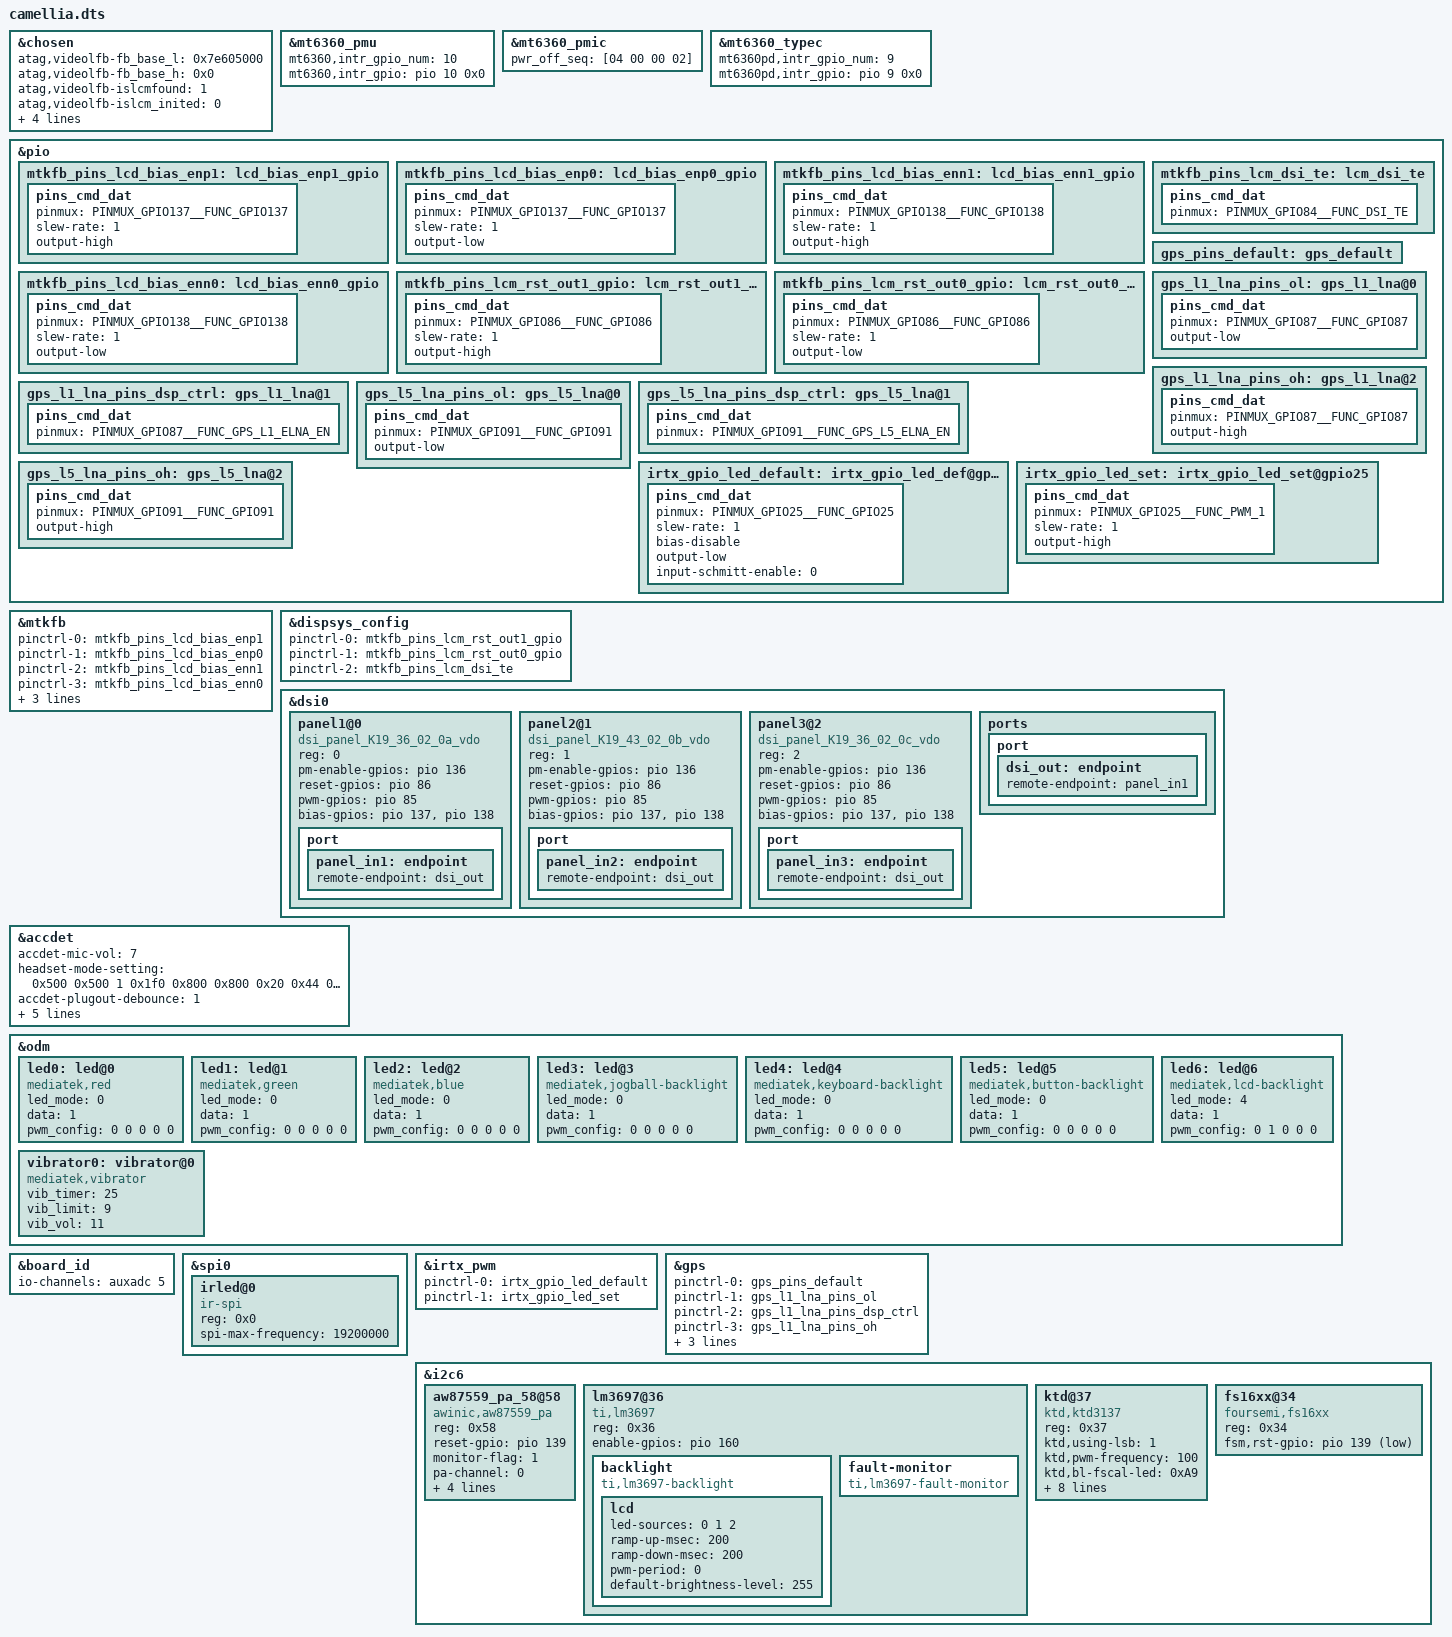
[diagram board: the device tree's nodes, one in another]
/*
 * Mediatek's mt6833 SoC device tree source
 *
 * Copyright (C) 2016 MediaTek Inc.
 * Copyright (C) 2021 XiaoMi, Inc.
 *
 * This program is free software; you can redistribute it and/or modify
 * it under the terms of the GNU General Public License version 2 as
 * published by the Free Software Foundation.
 *
 * This program is distributed in the hope that it will be useful,
 * but WITHOUT ANY WARRANTY; without even the implied warranty of
 * MERCHANTABILITY or FITNESS FOR A PARTICULAR PURPOSE.
 * See http://www.gnu.org/licenses/gpl-2.0.html for more details.
 */
/dts-v1/;
/plugin/;
#include <dt-bindings/interrupt-controller/irq.h>
#include <dt-bindings/interrupt-controller/arm-gic.h>
#ifndef CONFIG_FPGA_EARLY_PORTING
#include <dt-bindings/pinctrl/mt6833-pinfunc.h>
#endif

/* chosen */
&chosen {
	atag,videolfb-fb_base_l = <0x7e605000>;
	atag,videolfb-fb_base_h = <0x0>;
	atag,videolfb-islcmfound = <1>;
	atag,videolfb-islcm_inited = <0>;
	atag,videolfb-fps= <6000>;
	atag,videolfb-vramSize= <0x1be0000>;
	atag,videolfb-lcmname=
		"nt36672c_fhdp_dsi_vdo_90hz_tianma_lcm_drv";
};

&mt6360_pmu {
	mt6360,intr_gpio_num = <10>; /* direct defined GPIO num */
	mt6360,intr_gpio = <&pio 10 0x0>;
};

&mt6360_pmic {
	pwr_off_seq = [04 00 00 02];
};

/* BSP.Charge - 2020.11.02 - modify typec interrupt */
&mt6360_typec {
	mt6360pd,intr_gpio_num = <9>; /* direct defined GPIO num */
	mt6360pd,intr_gpio = <&pio 9 0x0>;
};

#ifndef CONFIG_FPGA_EARLY_PORTING
&pio {
	mtkfb_pins_lcd_bias_enp1: lcd_bias_enp1_gpio {
		pins_cmd_dat {
			pinmux = <PINMUX_GPIO137__FUNC_GPIO137>;
			slew-rate = <1>;
			output-high;
		};
	};

	mtkfb_pins_lcd_bias_enp0: lcd_bias_enp0_gpio {
		pins_cmd_dat {
			pinmux = <PINMUX_GPIO137__FUNC_GPIO137>;
			slew-rate = <1>;
			output-low;
		};
	};

	mtkfb_pins_lcd_bias_enn1: lcd_bias_enn1_gpio {
		pins_cmd_dat {
			pinmux = <PINMUX_GPIO138__FUNC_GPIO138>;
			slew-rate = <1>;
			output-high;
		};
	};

	mtkfb_pins_lcd_bias_enn0: lcd_bias_enn0_gpio {
		pins_cmd_dat {
			pinmux = <PINMUX_GPIO138__FUNC_GPIO138>;
			slew-rate = <1>;
			output-low;
		};
	};

	mtkfb_pins_lcm_rst_out1_gpio: lcm_rst_out1_gpio {
		pins_cmd_dat {
			pinmux = <PINMUX_GPIO86__FUNC_GPIO86>;
			slew-rate = <1>;
			output-high;
		};
	};

	mtkfb_pins_lcm_rst_out0_gpio: lcm_rst_out0_gpio {
		pins_cmd_dat {
			pinmux = <PINMUX_GPIO86__FUNC_GPIO86>;
			slew-rate = <1>;
			output-low;
		};
	};
	mtkfb_pins_lcm_dsi_te: lcm_dsi_te {
		pins_cmd_dat {
			pinmux = <PINMUX_GPIO84__FUNC_DSI_TE>;
		};
	};
};

&mtkfb {
	pinctrl-names = "lcd_bias_enp1_gpio", "lcd_bias_enp0_gpio",
		"lcd_bias_enn1_gpio", "lcd_bias_enn0_gpio",
		"lcm_rst_out1_gpio", "lcm_rst_out0_gpio",
		"mode_te_te";
	pinctrl-0 = <&mtkfb_pins_lcd_bias_enp1>;
	pinctrl-1 = <&mtkfb_pins_lcd_bias_enp0>;
	pinctrl-2 = <&mtkfb_pins_lcd_bias_enn1>;
	pinctrl-3 = <&mtkfb_pins_lcd_bias_enn0>;
	pinctrl-4 = <&mtkfb_pins_lcm_rst_out1_gpio>;
	pinctrl-5 = <&mtkfb_pins_lcm_rst_out0_gpio>;
	pinctrl-6 = <&mtkfb_pins_lcm_dsi_te>;
	status = "okay";
};
&dispsys_config {
	pinctrl-names =
		"lcm_rst_out1_gpio", "lcm_rst_out0_gpio",
		"mode_te_te";
	pinctrl-0 = <&mtkfb_pins_lcm_rst_out1_gpio>;
	pinctrl-1 = <&mtkfb_pins_lcm_rst_out0_gpio>;
	pinctrl-2 = <&mtkfb_pins_lcm_dsi_te>;
	status = "okay";
};

&dsi0 {
	status = "okay";
	#address-cells = <1>;
	#size-cells = <0>;
	/* BSP.lcm - 2020.11.19 - start */
	panel1@0 {
		compatible = "dsi_panel_K19_36_02_0a_vdo";
		reg = <0>;
		pm-enable-gpios = <&pio 136 0>;
		reset-gpios = <&pio 86 0>;
		pwm-gpios = <&pio 85 0>;
		bias-gpios = <&pio 137 0>,
			<&pio 138 0>;
		pinctrl-names = "default";
		port {
			panel_in1: endpoint {
				remote-endpoint = <&dsi_out>;
			};
		};
	};
	panel2@1 {
		compatible = "dsi_panel_K19_43_02_0b_vdo";
		reg = <1>;
		pm-enable-gpios = <&pio 136 0>;
		reset-gpios = <&pio 86 0>;
		pwm-gpios = <&pio 85 0>;
		bias-gpios = <&pio 137 0>,
			<&pio 138 0>;
		pinctrl-names = "default";
		port {
			panel_in2: endpoint {
				remote-endpoint = <&dsi_out>;
			};
		};
	};
	panel3@2 {
		compatible = "dsi_panel_K19_36_02_0c_vdo";
		reg = <2>;
		pm-enable-gpios = <&pio 136 0>;
		reset-gpios = <&pio 86 0>;
		pwm-gpios = <&pio 85 0>;
		bias-gpios = <&pio 137 0>,
			<&pio 138 0>;
		pinctrl-names = "default";
		port {
			panel_in3: endpoint {
				remote-endpoint = <&dsi_out>;
			};
		};
	};
	ports {
		port {
			dsi_out: endpoint {
				remote-endpoint = <&panel_in1>;
			};
		};
	};
};
#endif
/*BSP.Touch - Change dtsi file - 2020.11.18 - Start*/
/*#include "mediatek/cust_mt6833_touch_1080x2300.dtsi"*/
#include "mediatek/cust_mt6833_touch_1080x2400.dtsi"
/*BSP.Touch - Change dtsi file - 2020.11.18 - End*/
/* accdet start */
&accdet {
	/* accdet micbias voltage: 0x09:2.85v 0x08:2.8v 0x07,
	 * 2.7v;0x05,2.5v;0x02,1.9v
	 */
	/* BSP.audio - 2020.11.12 - modify to micbias of headphone start */
	accdet-mic-vol = <7>;
	/* BSP.audio - 2020.11.12 - modify to micbias of headphone end */
	/* accdet pwm_width, pwm_thresh, fall_delay, rise_delay
	 * debounce0, debounce1, debounce3, debounce4
	 * eint pwm_width, eint pwm_thresh
	 * eint deb(debounce0, debounce1, debounce2, debounce3), inv_debounce
	 */
	headset-mode-setting = <0x500 0x500 1 0x1f0
				0x800 0x800 0x20 0x44
				0x4 0x1
				0x5 0x3 0x3 0x5 0xe>;
	accdet-plugout-debounce = <1>;
	/*1:ACC mode, 2:low cost without in bias, 6:low cost with in bias*/
	accdet-mic-mode = <2>;
	/*0--MD_MAX--UP_MAX--DW_MAX*/
	headset-three-key-threshold = <0 80 220 400>;
	headset-three-key-threshold-CDD = <0 121 192 600>;
	/*0--MD_MAX--VOICE_MAX--UP_MAX--DW_MAX*/
	headset-four-key-threshold = <0 58 121 192 400>;

	/* select VTH to 2v and 500k, use internal resitance */
	eint_use_ext_res = <0>;
	status = "okay";
};
/* accdet end */

&odm {
	led0:led@0 {
		compatible = "mediatek,red";
		led_mode = <0>;
		data = <1>;
		pwm_config = <0 0 0 0 0>;
	};
	led1:led@1 {
		compatible = "mediatek,green";
		led_mode = <0>;
		data = <1>;
		pwm_config = <0 0 0 0 0>;
	};
	led2:led@2 {
		compatible = "mediatek,blue";
		led_mode = <0>;
		data = <1>;
		pwm_config = <0 0 0 0 0>;
	};
	led3:led@3 {
		compatible = "mediatek,jogball-backlight";
		led_mode = <0>;
		data = <1>;
		pwm_config = <0 0 0 0 0>;
	};
	led4:led@4 {
		compatible = "mediatek,keyboard-backlight";
		led_mode = <0>;
		data = <1>;
		pwm_config = <0 0 0 0 0>;
	};
	led5:led@5 {
		compatible = "mediatek,button-backlight";
		led_mode = <0>;
		data = <1>;
		pwm_config = <0 0 0 0 0>;
	};
	led6:led@6 {
		compatible = "mediatek,lcd-backlight";
		/* BSP.LCM - 2020.11.25 - modify to set brightness */
		led_mode = <4>;
		data = <1>;
		pwm_config = <0 1 0 0 0>;
	};
	vibrator0:vibrator@0 {
		compatible = "mediatek,vibrator";
		vib_timer = <25>;
		vib_limit = <9>;
	/* BSP.Charge - 2020.11.18 - Fixed the vibrator voltage */
		vib_vol= <11>;
	};
};
/* GPS GPIO standardization start */
&pio {
	gps_pins_default: gps_default {
	};

	gps_l1_lna_pins_ol: gps_l1_lna@0 {
		pins_cmd_dat {
			pinmux = <PINMUX_GPIO87__FUNC_GPIO87>;
			output-low;
		};
	};
	gps_l1_lna_pins_dsp_ctrl: gps_l1_lna@1 {
		pins_cmd_dat {
			pinmux = <PINMUX_GPIO87__FUNC_GPS_L1_ELNA_EN>;
		};
	};
	gps_l1_lna_pins_oh: gps_l1_lna@2 {
		pins_cmd_dat {
			pinmux = <PINMUX_GPIO87__FUNC_GPIO87>;
			output-high;
		};
	};

	gps_l5_lna_pins_ol: gps_l5_lna@0 {
		pins_cmd_dat {
			pinmux = <PINMUX_GPIO91__FUNC_GPIO91>;
			output-low;
		};
	};
	gps_l5_lna_pins_dsp_ctrl: gps_l5_lna@1 {
		pins_cmd_dat {
			pinmux = <PINMUX_GPIO91__FUNC_GPS_L5_ELNA_EN>;
		};
	};
	gps_l5_lna_pins_oh: gps_l5_lna@2 {
		pins_cmd_dat {
			pinmux = <PINMUX_GPIO91__FUNC_GPIO91>;
			output-high;
		};
	};
};
/*BSP.System - 2020.11.5 - add board id*/
&board_id {
	io-channels = <&auxadc 5>;
	io-channel-names = "board_id-channel";
	status = "okay";
};

&spi0 {
	status = "ok";
	irled@0 {
		compatible = "ir-spi";
		reg = <0x0>;
		//vdd-supply = <&pm8953_l8>; //vdd
		status = "ok";
		spi-max-frequency = <19200000>;
	};
};

&pio {
	/* IRTX GPIO Settings -Start */
	/* default: GPIO0, output, high */
	irtx_gpio_led_default:irtx_gpio_led_def@gpio25 {
		pins_cmd_dat {
			pinmux = <PINMUX_GPIO25__FUNC_GPIO25>;
			slew-rate = <1>;
			bias-disable;
			output-low;
			input-schmitt-enable = <0>;
		};
	};

	irtx_gpio_led_set:irtx_gpio_led_set@gpio25 {
		pins_cmd_dat {
			pinmux = <PINMUX_GPIO25__FUNC_PWM_1>;
			slew-rate = <1>;
			output-high;
		};
	};
}; /* IRTX GPIO Settings -End */

&irtx_pwm {
	pinctrl-names = "irtx_gpio_led_default", "irtx_gpio_led_set";
	pinctrl-0 = <&irtx_gpio_led_default>;
	pinctrl-1 = <&irtx_gpio_led_set>;
	status = "okay";
};

&gps {
	pinctrl-names = "default",
		"gps_l1_lna_disable",
		"gps_l1_lna_dsp_ctrl",
		"gps_l1_lna_enable",
		"gps_l5_lna_disable",
		"gps_l5_lna_dsp_ctrl",
		"gps_l5_lna_enable";
	pinctrl-0 = <&gps_pins_default>;
	pinctrl-1 = <&gps_l1_lna_pins_ol>;
	pinctrl-2 = <&gps_l1_lna_pins_dsp_ctrl>;
	pinctrl-3 = <&gps_l1_lna_pins_oh>;
	pinctrl-4 = <&gps_l5_lna_pins_ol>;
	pinctrl-5 = <&gps_l5_lna_pins_dsp_ctrl>;
	pinctrl-6 = <&gps_l5_lna_pins_oh>;
	status = "okay";
};
/* GPS GPIO standardization end */

/* BSP.Audio - 2020.11.2 - modify to bring up PA */
&i2c6 {
	aw87559_pa_58@58 {
		compatible = "awinic,aw87559_pa";
		reg = <0x58>;
		reset-gpio = <&pio 139 0>;
		monitor-flag = <1>;
		pa-channel = < 0 >;
		actflag-gain-array = < 0x00 0x08 0x08 0x08 0x00 >;
		gain-reg-addr = <0x06>;
		monitor-timer-val = <3000>;
		monitor-timer-count-max = <5>;
		status = "okay";
	};
};
/* end modify*/
/* BSP.LCM - 2020.11.14 - modify to set brightness */
&i2c6 {
	lm3697@36 {
		compatible = "ti,lm3697";
		reg = <0x36>;
		status = "okay";
		enable-gpios = <&pio 160 0>;
		backlight {
			compatible = "ti,lm3697-backlight";
			lcd {
				led-sources = <0 1 2>;
				ramp-up-msec = <200>;
				ramp-down-msec = <200>;
				pwm-period = <0>;
				default-brightness-level = <255>;
			};
		};
		fault-monitor {
			compatible = "ti,lm3697-fault-monitor";
		};
	};


	ktd@37 {
		compatible = "ktd,ktd3137";
		reg = <0x37>;
		status = "okay";
		/*ktd,pwm-mode; */
		ktd,using-lsb = <1>;
		ktd,pwm-frequency = <100>;
		ktd,bl-fscal-led = <0xA9>;/*default 21.8mA*/
		ktd,turn-on-ramp = <0>;
		ktd,turn-off-ramp = <0>;
		ktd,pwm-trans-dim = <0>;
		ktd,i2c-trans-dim = <0>;
		ktd,bl-channel = <2>;
		ktd,ovp-level = <32>; /*default 32v*/
		ktd,switching-frequency = <1000>; /*default 1000kHz*/
		ktd,inductor-current = <2600>; //default 2600mA
		//ktd,linear_ramp = <1>; /*default is exponential*/
		//ktd,linear_backlight = <1>; /*default is exponential*/
		};
};
/* end modify*/

/* BSP.Audio - 2020.11.11 - modify to bring up second PA */
&i2c6 {
	fs16xx@34 {
		compatible = "foursemi,fs16xx";
		reg = <0x34>;
		fsm,rst-gpio = <&pio 139 1>;
		status = "okay";
	};
};
/* end modify*/
#include "mediatek/cust_camellia_camera.dtsi"
#include <camellia/cust.dtsi>
#include "mediatek/cust_camellia_fingerprint.dtsi"

/*End of this file, DO NOT ADD ANYTHING HERE*/
